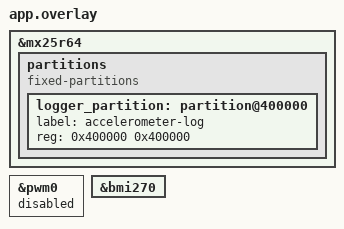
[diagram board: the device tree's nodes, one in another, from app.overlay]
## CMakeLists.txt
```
cmake_minimum_required(VERSION 3.20.0)
find_package(Zephyr REQUIRED HINTS $ENV{ZEPHYR_BASE})
project(thingy53_logger)
target_sources(app PRIVATE src/main.c src/button.c src/storage.c src/usb.c src/writer.c src/imu_temperature.c)
```

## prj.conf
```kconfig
CONFIG_GPIO=y
CONFIG_SENSOR=y
CONFIG_ADXL362=y
CONFIG_ADXL362_ACCEL_RANGE_4G=y
CONFIG_ADXL362_ACCEL_ODR_100=y
CONFIG_ADXL362_TRIGGER_OWN_THREAD=y
CONFIG_ADXL362_THREAD_STACK_SIZE=2048
CONFIG_BMI270=y
CONFIG_FLASH=y
CONFIG_FLASH_MAP=y
CONFIG_NORDIC_QSPI_NOR=y
CONFIG_CRC=y
CONFIG_SERIAL=y
CONFIG_UART_INTERRUPT_DRIVEN=y
CONFIG_UART_LINE_CTRL=y
CONFIG_USB_DEVICE_STACK_NEXT=y
CONFIG_CDC_ACM_SERIAL_INITIALIZE_AT_BOOT=y
CONFIG_CDC_ACM_SERIAL_PRODUCT_STRING="Thingy53 Accelerometer Logger"
CONFIG_CONSOLE=n
CONFIG_UART_CONSOLE=n
CONFIG_LOG=n
CONFIG_BOOT_BANNER=n
CONFIG_BOOTLOADER_MCUBOOT=n
CONFIG_BOARD_ENABLE_CPUNET=n
CONFIG_MAIN_STACK_SIZE=4096
CONFIG_ASSERT=y
```

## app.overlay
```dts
/* Keep the lower half of the 8 MiB external flash outside the logger. */
&mx25r64 {
	partitions {
		compatible = "fixed-partitions";
		#address-cells = <1>;
		#size-cells = <1>;

		logger_partition: partition@400000 {
			label = "accelerometer-log";
			reg = <0x400000 0x400000>;
		};
	};
};

/* The application uses GPIO LEDs, not the board's PWM LED driver. */
&pwm0 {
	status = "disabled";
};

/* The Thingy:53 BMI270 IMU supplies the gyroscope; it shares the SPI bus with the ADXL362. */
&bmi270 {
	status = "okay";
};
```

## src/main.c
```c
#include "button.h"
#include "imu_temperature.h"
#include "sensor_raw.h"
#include "storage.h"
#include "usb.h"
#include "writer.h"

#include <errno.h>
#include <stdio.h>
#include <string.h>
#include <zephyr/drivers/gpio.h>
#include <zephyr/drivers/sensor.h>
#include <zephyr/kernel.h>
#include <zephyr/sys/atomic.h>

static const struct device *const accel = DEVICE_DT_GET(DT_ALIAS(accel0));
static const struct device *const imu = DEVICE_DT_GET(DT_NODELABEL(bmi270));
static const struct gpio_dt_spec button = GPIO_DT_SPEC_GET(DT_ALIAS(sw0), gpios);
static const struct gpio_dt_spec red = GPIO_DT_SPEC_GET(DT_ALIAS(led0), gpios);
static const struct gpio_dt_spec green = GPIO_DT_SPEC_GET(DT_ALIAS(led1), gpios);
static const struct gpio_dt_spec blue = GPIO_DT_SPEC_GET(DT_ALIAS(led2), gpios);
static const struct sensor_trigger trigger = {
	.type = SENSOR_TRIG_DATA_READY,
	.chan = SENSOR_CHAN_ACCEL_XYZ,
};
K_MUTEX_DEFINE(capture_lock);
static bool recording;
static bool downloading;
static bool storage_ready;
static bool fatal;
static int last_error;
static int64_t erase_done_ms;
static atomic_t capture_error;
static uint64_t start_us;
static uint64_t previous_us;
static uint32_t download_page;
static uint32_t download_offset;
static int64_t download_progress;
static uint8_t download_buffer[LOG_PAGE_SIZE] __aligned(4);
static char reply[192];
static size_t reply_size;

static uint64_t now_us(void)
{
	return k_ticks_to_us_floor64(k_uptime_ticks());
}

static void data_ready(const struct device *dev, const struct sensor_trigger *trig)
{
	ARG_UNUSED(trig);
	struct sensor_value xyz[3];
	struct sensor_value gyro[3];
	struct log_sample sample;

	k_mutex_lock(&capture_lock, K_FOREVER);
	uint64_t timestamp = now_us();
	int rc = sensor_sample_fetch(dev);

	if (!rc) {
		rc = sensor_channel_get(dev, SENSOR_CHAN_ACCEL_XYZ, xyz);
	}
	/* The gyroscope runs at 200 Hz, so this read is at most 5 ms old. */
	if (!rc) {
		rc = sensor_sample_fetch(imu);
	}
	if (!rc) {
		rc = sensor_channel_get(imu, SENSOR_CHAN_GYRO_XYZ, gyro);
	}
	if (!rc) {
		rc = imu_temperature_read(&sample.temperature_raw);
	}
	if (recording && !atomic_get(&capture_error)) {
		if (!rc && previous_us && timestamp - previous_us > 15000) {
			rc = -EOVERFLOW;
		}
		previous_us = timestamp;
		if (!rc) {
			sample.time_us = timestamp - start_us;
			for (int i = 0; i < 3; i++) {
				sample.accel[i] = adxl362_raw_from_micro_ms2(sensor_value_to_micro(&xyz[i]));
				sample.gyro[i] = bmi270_raw_from_micro_rad_s(sensor_value_to_micro(&gyro[i]));
			}
			rc = writer_append(&sample);
		}
		if (rc) {
			/* Keep the first cause; later callbacks are ignored until stop. */
			atomic_cas(&capture_error, 0, rc);
		}
	}
	k_mutex_unlock(&capture_lock);
}

static void error(int rc)
{
	if (rc < 0) {
		last_error = rc;
	}
}

static void stop(void)
{
	k_mutex_lock(&capture_lock, K_FOREVER);
	recording = false;
	error(atomic_set(&capture_error, 0));
	k_mutex_unlock(&capture_lock);
	error(writer_flush());
}

static void toggle(void)
{
	if (fatal || downloading) {
		return;
	}
	if (recording) {
		stop();
		return;
	}
	int rc = writer_begin();

	if (rc) {
		error(rc);
		return;
	}
	atomic_clear(&capture_error);
	last_error = 0;
	k_mutex_lock(&capture_lock, K_FOREVER);
	start_us = now_us();
	previous_us = 0;
	recording = true;
	k_mutex_unlock(&capture_lock);
}

static void erase_blink(struct k_timer *timer)
{
	ARG_UNUSED(timer);
	gpio_pin_toggle_dt(&blue);
}

K_TIMER_DEFINE(erase_blink_timer, erase_blink, NULL);

static void erase(void)
{
	if (!storage_ready) {
		return;
	}
	if (recording) {
		stop();
	}
	downloading = false;
	reply_size = 0;
	logger_usb_discard();
	/* The erase blocks for a long time; a timer keeps blue blinking meanwhile. */
	error(gpio_pin_set_dt(&blue, 1));
	k_timer_start(&erase_blink_timer, K_MSEC(250), K_MSEC(250));
	int rc = storage_erase();

	k_timer_stop(&erase_blink_timer);

	if (rc) {
		/* Partial erase requires a reboot/re-scan before appending. */
		fatal = true;
		error(rc);
	} else {
		erase_done_ms = k_uptime_get();
		if (!fatal) {
			last_error = 0;
		}
	}
}

/* After a successful erase, blue flashes three times (150 ms off, 150 ms on). */
static bool erase_flash_active(bool *on)
{
	if (!erase_done_ms) {
		return false;
	}
	int64_t phase = (k_uptime_get() - erase_done_ms) / 150;

	if (phase >= 6) {
		erase_done_ms = 0;
		return false;
	}
	*on = phase & 1;
	return true;
}

static void poll_button(void)
{
	static struct button_state state;
	int value = gpio_pin_get_dt(&button);

	if (value < 0) {
		error(value);
		return;
	}
	switch (button_update(&state, value != 0, k_uptime_get())) {
	case BUTTON_TOGGLE:
		toggle();
		break;
	case BUTTON_ERASE:
		erase();
		break;
	case BUTTON_NONE:
		break;
	}
}

static void poll_usb(void)
{
	char command[32];

	if (!logger_usb_connected()) {
		downloading = false;
		reply_size = 0;
		logger_usb_discard();
		return;
	}
	if (reply_size) {
		if (logger_usb_send(reply, reply_size)) {
			reply_size = 0;
		}
		return;
	}
	if (downloading) {
		if (k_uptime_get() - download_progress > 10000) {
			downloading = false;
			logger_usb_discard();
			error(-ETIMEDOUT);
			return;
		}
		if (download_page == storage.used) {
			memcpy(reply, "END\n", 4);
			reply_size = 4;
			downloading = false;
			return;
		}
		if (!download_offset) {
			int rc = storage_read(download_page, download_buffer);

			if (rc) {
				error(rc);
				downloading = false;
				reply_size = snprintf(reply, sizeof(reply), "ERR read %d\n", rc);
				return;
			}
		}
		if (logger_usb_send(download_buffer + download_offset, 256)) {
			download_progress = k_uptime_get();
			download_offset += 256;
			if (download_offset == LOG_PAGE_SIZE) {
				download_page++;
				download_offset = 0;
			}
		}
		return;
	}
	if (!logger_usb_command(command, sizeof(command))) {
		return;
	}
	if (!strcmp(command, "STATUS")) {
		reply_size = snprintf(reply, sizeof(reply),
			"STATUS %s pages=%u capacity=%u session=%u invalid=%u error=%d\n",
			fatal ? "fault" : recording ? "recording" : "stopped",
			storage.used, storage.capacity, storage.session,
			storage.invalid, last_error);
	} else if (!strcmp(command, "DUMP")) {
		if (recording || fatal) {
			reply_size = snprintf(reply, sizeof(reply), "ERR %s\n",
					      recording ? "recording" : "fault");
		} else {
			downloading = true;
			download_page = 0;
			download_offset = 0;
			download_progress = k_uptime_get();
			reply_size = snprintf(reply, sizeof(reply), "BEGIN %u\n", storage.used);
		}
	} else {
		reply_size = snprintf(reply, sizeof(reply), "ERR unknown-command\n");
	}
}

static int configure_gyro(void)
{
	struct sensor_value odr = {.val1 = 200};
	struct sensor_value range = {.val1 = LOG_GYRO_RANGE_DPS};
	int rc = sensor_attr_set(imu, SENSOR_CHAN_GYRO_XYZ, SENSOR_ATTR_FULL_SCALE, &range);

	if (!rc) {
		rc = sensor_attr_set(imu, SENSOR_CHAN_GYRO_XYZ, SENSOR_ATTR_SAMPLING_FREQUENCY, &odr);
	}
	return rc;
}

int main(void)
{
	const struct gpio_dt_spec *leds[] = {&red, &green, &blue};
	int rc;

	for (size_t i = 0; i < ARRAY_SIZE(leds); i++) {
		if (!gpio_is_ready_dt(leds[i])) {
			return -ENODEV;
		}
		rc = gpio_pin_configure_dt(leds[i], GPIO_OUTPUT_INACTIVE);
		if (rc) {
			return rc;
		}
	}
	rc = logger_usb_init();
	if (rc) {
		error(rc);
		fatal = true;
	}
	rc = storage_init();
	storage_ready = rc == 0;
	if (rc) {
		error(rc);
		fatal = true;
	}
	if (!gpio_is_ready_dt(&button)) {
		rc = -ENODEV;
	} else {
		rc = gpio_pin_configure_dt(&button, GPIO_INPUT);
	}
	if (!rc && (!device_is_ready(accel) || !device_is_ready(imu))) {
		rc = -ENODEV;
	}
	if (!rc) {
		rc = configure_gyro();
	}
	if (!rc) {
		rc = sensor_trigger_set(accel, &trigger, data_ready);
	}
	if (rc) {
		error(rc);
		fatal = true;
	}
	while (true) {
		if (recording) {
			int capture_rc = atomic_set(&capture_error, 0);

			error(writer_take_error());
			if (capture_rc || last_error || writer_full()) {
				error(capture_rc);
				if (!last_error) {
					error(-ENOSPC);
				}
				stop();
			}
		}
		poll_button();
		poll_usb();
		error(gpio_pin_set_dt(&red, last_error != 0 || storage.invalid != 0));
		error(gpio_pin_set_dt(&green, recording));
		bool blue_on = downloading || (!recording && !last_error);
		bool flash_on;

		if (erase_flash_active(&flash_on)) {
			blue_on = flash_on;
		}
		error(gpio_pin_set_dt(&blue, blue_on));
		k_sleep(K_MSEC(1));
	}
	return 0;
}
```

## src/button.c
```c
#include "button.h"

enum button_event button_update(struct button_state *state, bool active, int64_t now_ms)
{
	if (active != state->raw) {
		state->raw = active;
		state->changed = now_ms;
	}
	if (state->raw != state->stable && now_ms - state->changed >= 30) {
		state->stable = state->raw;
		if (state->stable) {
			state->pressed = now_ms;
			state->held = false;
		} else if (!state->held) {
			return BUTTON_TOGGLE;
		}
	}
	if (state->raw && state->stable && !state->held &&
	    now_ms - state->pressed >= 5000) {
		state->held = true;
		return BUTTON_ERASE;
	}
	return BUTTON_NONE;
}
```

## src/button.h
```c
#ifndef LOGGER_BUTTON_H
#define LOGGER_BUTTON_H

#include <stdbool.h>
#include <stdint.h>

enum button_event {
	BUTTON_NONE,
	BUTTON_TOGGLE,
	BUTTON_ERASE,
};

struct button_state {
	bool raw;
	bool stable;
	bool held;
	int64_t changed;
	int64_t pressed;
};

enum button_event button_update(struct button_state *state, bool active, int64_t now_ms);

#endif
```

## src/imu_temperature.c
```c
#include "imu_temperature.h"

#include <errno.h>
#include <zephyr/drivers/spi.h>
#include <zephyr/kernel.h>
#include <zephyr/sys/byteorder.h>

static const struct spi_dt_spec bus = SPI_DT_SPEC_GET(
	DT_NODELABEL(bmi270), SPI_WORD_SET(8) | SPI_TRANSFER_MSB, 0);

int imu_temperature_read(int16_t *raw)
{
	uint8_t address = 0x22 | 0x80;
	uint8_t discarded[2];
	uint8_t bytes[2];
	struct spi_buf tx_buffer = {.buf = &address, .len = 1};
	struct spi_buf rx_buffers[] = {
		/* nrfx needs a real DMA buffer to clock bytes after command TX ends. */
		{.buf = discarded, .len = sizeof(discarded)},
		{.buf = bytes, .len = sizeof(bytes)},
	};
	const struct spi_buf_set tx = {.buffers = &tx_buffer, .count = 1};
	const struct spi_buf_set rx = {.buffers = rx_buffers, .count = 2};
	int rc = spi_transceive_dt(&bus, &tx, &rx);

	if (rc) {
		return rc;
	}
	k_usleep(2);
	int16_t value = (int16_t)sys_get_le16(bytes);

	if (value == INT16_MIN) {
		return -ENODATA;
	}
	*raw = value;
	return 0;
}
```

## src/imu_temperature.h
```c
#ifndef LOGGER_IMU_TEMPERATURE_H
#define LOGGER_IMU_TEMPERATURE_H

#include <stdint.h>

int imu_temperature_read(int16_t *raw);

#endif
```

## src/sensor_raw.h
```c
#ifndef LOGGER_SENSOR_RAW_H
#define LOGGER_SENSOR_RAW_H

#include <stdint.h>

/*
 * Zephyr's sensor API only returns converted values. These helpers undo the
 * drivers' integer conversions so the raw 16-bit counts can be stored. One
 * count is about 19,600 micro-m/s^2 or 1,065 micro-rad/s, far larger than the
 * drivers' rounding error, so rounding to the nearest count is exact.
 */
#define SENSOR_RAW_G_MICRO 9806650LL      /* Zephyr SENSOR_G */
#define SENSOR_RAW_PI_MICRO 3141592LL     /* Zephyr SENSOR_PI */
#define ADXL362_4G_COUNTS_PER_G 500LL     /* ADXL362 driver, +/-4 g range */
#define BMI270_GYRO_FULL_SCALE_COUNTS 32767LL /* BMI270 driver, INT16_MAX */

static inline int16_t sensor_raw_clamp(int64_t counts)
{
	return counts > INT16_MAX ? INT16_MAX : counts < INT16_MIN ? INT16_MIN : (int16_t)counts;
}

static inline int64_t sensor_raw_divide_round(int64_t numerator, int64_t denominator)
{
	return (numerator + (numerator < 0 ? -denominator / 2 : denominator / 2)) / denominator;
}

/* ADXL362 acceleration in micro-m/s^2 to raw counts (driver: counts * G / 500). */
static inline int16_t adxl362_raw_from_micro_ms2(int64_t micro_ms2)
{
	return sensor_raw_clamp(sensor_raw_divide_round(micro_ms2 * ADXL362_4G_COUNTS_PER_G,
							SENSOR_RAW_G_MICRO));
}

/* BMI270 rate in micro-rad/s to raw counts at +/-2000 deg/s. */
static inline int16_t bmi270_raw_from_micro_rad_s(int64_t micro_rad_s)
{
	return sensor_raw_clamp(sensor_raw_divide_round(
		micro_rad_s * 180LL * BMI270_GYRO_FULL_SCALE_COUNTS,
		2000LL * SENSOR_RAW_PI_MICRO));
}

#endif
```

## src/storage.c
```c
#include "storage.h"

#include <errno.h>
#include <string.h>
#include <zephyr/storage/flash_map.h>
#include <zephyr/sys/crc.h>

struct log_storage storage;
static const struct flash_area *area;
static uint8_t page[LOG_PAGE_SIZE] __aligned(4);

static bool erased(const uint8_t *data)
{
	for (size_t i = 0; i < LOG_PAGE_SIZE; i++) {
		if (data[i] != 0xff) {
			return false;
		}
	}
	return true;
}

static bool valid(const uint8_t *data)
{
	const struct log_page_image *image = (const void *)data;
	const struct log_page_header *h = &image->header;
	uint16_t max_count;

	switch (h->version) {
	case LOG_VERSION_1:
		max_count = LOG_V3_SAMPLES_PER_PAGE;
		break;
	case LOG_VERSION_2:
		max_count = LOG_V2_SAMPLES_PER_PAGE;
		if (h->gyro_range_dps != LOG_GYRO_RANGE_DPS) {
			return false;
		}
		break;
	case LOG_VERSION_3:
	case LOG_VERSION:
		max_count = h->version == LOG_VERSION ? LOG_SAMPLES_PER_PAGE : LOG_V3_SAMPLES_PER_PAGE;
		if (h->gyro_range_dps != LOG_GYRO_RANGE_DPS ||
		    h->accel_counts_per_g != LOG_ACCEL_COUNTS_PER_G) {
			return false;
		}
		break;
	default:
		return false;
	}
	return h->magic == LOG_MAGIC && h->count > 0 && h->count <= max_count &&
	       h->session != 0 && h->sample_rate_hz == LOG_SAMPLE_RATE_HZ &&
	       h->range_g == LOG_RANGE_G &&
	       image->crc32 == crc32_ieee(data, LOG_PAGE_SIZE - sizeof(image->crc32));
}

int storage_read(uint32_t index, uint8_t *buffer)
{
	if (index >= storage.capacity) {
		return -EINVAL;
	}
	return flash_area_read(area, index * LOG_PAGE_SIZE, buffer, LOG_PAGE_SIZE);
}

int storage_init(void)
{
	int rc = flash_area_open(PARTITION_ID(logger_partition), &area);

	if (rc) {
		return rc;
	}
	memset(&storage, 0, sizeof(storage));
	if (!flash_area_device_is_ready(area) || area->fa_size % LOG_PAGE_SIZE) {
		return -ENODEV;
	}
	storage.capacity = area->fa_size / LOG_PAGE_SIZE;
	for (uint32_t i = 0; i < storage.capacity; i++) {
		rc = storage_read(i, page);
		if (rc) {
			return rc;
		}
		if (erased(page)) {
			continue;
		}
		/* Never reuse a possibly torn write without an explicit erase. */
		storage.used = i + 1;
		if (!valid(page) || ((const struct log_page_image *)page)->header.page_index != i) {
			storage.invalid++;
			continue;
		}
		uint32_t session = ((const struct log_page_image *)page)->header.session;

		if (session > storage.session) {
			storage.session = session;
		}
	}
	return 0;
}

int storage_begin(void)
{
	if (storage.used == storage.capacity) {
		return -ENOSPC;
	}
	if (storage.session == UINT32_MAX) {
		return -EOVERFLOW;
	}
	storage.session++;
	return 0;
}

void storage_page_reset(struct log_page *p)
{
	memset(p->data, 0xff, sizeof(p->data));
	p->count = 0;
}

int storage_page_add(struct log_page *p, const struct log_sample *sample)
{
	if (p->count == LOG_SAMPLES_PER_PAGE) {
		return -ENOSPC;
	}
	struct log_sample_record *record = &p->image.samples[p->count];

	record->time_us = sample->time_us;
	record->temperature_raw = sample->temperature_raw;
	for (int i = 0; i < 3; i++) {
		record->accel_raw[i] = sample->accel[i];
		record->gyro_raw[i] = sample->gyro[i];
	}
	p->count++;
	return 0;
}

int storage_write_page(struct log_page *p)
{
	struct log_page_header *h = &p->image.header;

	h->magic = LOG_MAGIC;
	h->version = LOG_VERSION;
	h->count = p->count;
	h->session = storage.session;
	h->page_index = p->slot;
	h->sample_rate_hz = LOG_SAMPLE_RATE_HZ;
	h->range_g = LOG_RANGE_G;
	h->gyro_range_dps = LOG_GYRO_RANGE_DPS;
	h->accel_counts_per_g = LOG_ACCEL_COUNTS_PER_G;
	p->image.crc32 = crc32_ieee(p->data, LOG_PAGE_SIZE - sizeof(p->image.crc32));
	int rc = flash_area_write(area, p->slot * LOG_PAGE_SIZE, p->data, LOG_PAGE_SIZE);

	/* A failed write may have programmed some bits. Do not retry that slot. */
	storage.used = p->slot + 1;
	if (rc) {
		storage.invalid++;
	}
	return rc;
}

int storage_erase(void)
{
	int rc = flash_area_erase(area, 0, area->fa_size);

	if (rc) {
		return rc;
	}
	storage.used = 0;
	storage.session = 0;
	storage.invalid = 0;
	return 0;
}
```

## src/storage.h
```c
#ifndef LOGGER_STORAGE_H
#define LOGGER_STORAGE_H

#include <stddef.h>
#include <stdint.h>

#define LOG_PAGE_SIZE 4096U
#define LOG_HEADER_SIZE 32U
#define LOG_SAMPLE_SIZE 22U
#define LOG_SAMPLES_PER_PAGE 184U
#define LOG_MAGIC 0x33474c41U /* "ALG3" when read as little-endian bytes */
#define LOG_VERSION 4U
/*
 * Older pages stay readable: version 1 (accelerometer only, converted values) and
 * version 2 (converted accelerometer + gyroscope, 126 per page), and version 3
 * (raw accelerometer + gyroscope, 203 per page).
 */
#define LOG_VERSION_1 1U
#define LOG_VERSION_2 2U
#define LOG_VERSION_3 3U
#define LOG_V3_SAMPLES_PER_PAGE 203U
#define LOG_V2_SAMPLES_PER_PAGE 126U
#define LOG_SAMPLE_RATE_HZ 100U
#define LOG_RANGE_G 4U
#define LOG_ACCEL_COUNTS_PER_G 500U
#define LOG_GYRO_RANGE_DPS 2000U

/* Sample as captured in RAM; accelerometer and gyroscope are raw 16-bit counts. */
struct log_sample {
	uint64_t time_us;
	int16_t accel[3];
	int16_t gyro[3];
	int16_t temperature_raw; /* BMI270: Celsius = 23 + raw / 512. */
};

/*
 * On-flash layout, little-endian, one page per 4096-byte flash slot. See
 * docs/log-format.md; keep it, docs/thingy53_log.ksy and tools/logger.py in
 * sync with these structures.
 */
struct __attribute__((packed)) log_page_header {
	uint32_t magic;
	uint16_t version;
	uint16_t count;       /* valid samples in this page, 1..184 */
	uint32_t session;     /* recording session, starts at 1 */
	uint32_t page_index;  /* physical slot number of this page */
	uint32_t sample_rate_hz;
	uint32_t range_g;
	uint32_t gyro_range_dps; /* versions 2..4; erased (0xffffffff) in version 1 */
	uint16_t accel_counts_per_g; /* versions 3 and 4 */
	uint16_t reserved;    /* left erased (0xffff) */
};

struct __attribute__((packed)) log_sample_record {
	uint64_t time_us;     /* microseconds since the recording started */
	int16_t accel_raw[3]; /* x, y, z accelerometer counts */
	int16_t gyro_raw[3];  /* x, y, z gyroscope counts */
	int16_t temperature_raw;
};

struct __attribute__((packed)) log_page_image {
	struct log_page_header header;
	struct log_sample_record samples[LOG_SAMPLES_PER_PAGE]; /* unused ones stay 0xff */
	uint8_t padding[12];  /* left erased */
	uint32_t crc32;       /* CRC-32/IEEE of all preceding bytes of the page */
};

_Static_assert(__BYTE_ORDER__ == __ORDER_LITTLE_ENDIAN__, "page format is little-endian");
_Static_assert(sizeof(struct log_page_header) == LOG_HEADER_SIZE, "header size");
_Static_assert(sizeof(struct log_sample_record) == LOG_SAMPLE_SIZE, "sample size");
_Static_assert(sizeof(struct log_page_image) == LOG_PAGE_SIZE, "page size");

struct log_page {
	_Alignas(4) union {
		uint8_t data[LOG_PAGE_SIZE];
		struct log_page_image image;
	};
	uint16_t count;
	uint32_t slot;
};

struct log_storage {
	uint32_t used;
	uint32_t capacity;
	uint32_t session;
	uint32_t invalid;
};

extern struct log_storage storage;

int storage_init(void);
int storage_begin(void);
void storage_page_reset(struct log_page *page);
int storage_page_add(struct log_page *page, const struct log_sample *sample);
int storage_write_page(struct log_page *page);
int storage_erase(void);
int storage_read(uint32_t index, uint8_t *buffer);

#endif
```

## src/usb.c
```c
#include "usb.h"

#include <errno.h>
#include <string.h>
#include <zephyr/device.h>
#include <zephyr/drivers/uart.h>
#include <zephyr/kernel.h>
#include <zephyr/sys/ring_buffer.h>

static const struct device *const uart = DEVICE_DT_GET(DT_NODELABEL(board_cdc_acm_uart));
RING_BUF_DECLARE(tx, 2048);
RING_BUF_DECLARE(rx, 256);
static struct k_spinlock lock;

static void interrupt(const struct device *dev, void *user_data)
{
	ARG_UNUSED(user_data);
	if (!uart_irq_update(dev)) {
		return;
	}
	/* Drain all pending RX bytes, otherwise the driver re-queues this callback. */
	while (uart_irq_rx_ready(dev)) {
		uint8_t buffer[64];
		int n = uart_fifo_read(dev, buffer, sizeof(buffer));

		if (n <= 0) {
			break;
		}
		ring_buf_put(&rx, buffer, n);
	}
	if (uart_irq_tx_ready(dev)) {
		k_spinlock_key_t key = k_spin_lock(&lock);
		uint8_t *data;
		uint32_t size = ring_buf_get_claim(&tx, &data, 256);

		if (size) {
			int n = uart_fifo_fill(dev, data, size);

			ring_buf_get_finish(&tx, n > 0 ? n : 0);
		}
		if (ring_buf_is_empty(&tx)) {
			uart_irq_tx_disable(dev);
		}
		k_spin_unlock(&lock, key);
	}
}

int logger_usb_init(void)
{
	if (!device_is_ready(uart)) {
		return -ENODEV;
	}
	int rc = uart_irq_callback_user_data_set(uart, interrupt, NULL);

	if (rc) {
		return rc;
	}
	/* With a callback set, the CDC ACM driver only starts USB OUT transfers once RX is enabled. */
	uart_irq_rx_enable(uart);
	return 0;
}

bool logger_usb_connected(void)
{
	uint32_t dtr = 0;

	return uart_line_ctrl_get(uart, UART_LINE_CTRL_DTR, &dtr) == 0 && dtr;
}

bool logger_usb_send(const void *data, size_t size)
{
	if (!logger_usb_connected()) {
		return false;
	}
	k_spinlock_key_t key = k_spin_lock(&lock);
	bool fits = ring_buf_space_get(&tx) >= size;

	if (fits) {
		ring_buf_put(&tx, data, size);
		uart_irq_tx_enable(uart);
	}
	k_spin_unlock(&lock, key);
	return fits;
}

void logger_usb_discard(void)
{
	k_spinlock_key_t key = k_spin_lock(&lock);

	uart_irq_tx_disable(uart);
	ring_buf_reset(&tx);
	k_spin_unlock(&lock, key);
}

bool logger_usb_command(char *command, size_t capacity)
{
	static char input[32];
	static size_t length;
	static bool overflow;
	uint8_t c;

	while (ring_buf_get(&rx, &c, 1) == 1) {
		if (c == '\r') {
			continue;
		}
		if (c == '\n') {
			if (overflow || length >= capacity) {
				strncpy(command, "INVALID", capacity);
				command[capacity - 1] = '\0';
			} else {
				memcpy(command, input, length);
				command[length] = '\0';
			}
			length = 0;
			overflow = false;
			return true;
		}
		if (length < sizeof(input) - 1) {
			input[length++] = c;
		} else {
			overflow = true;
		}
	}
	return false;
}
```

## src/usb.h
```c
#ifndef LOGGER_USB_H
#define LOGGER_USB_H

#include <stdbool.h>
#include <stddef.h>

int logger_usb_init(void);
bool logger_usb_connected(void);
bool logger_usb_send(const void *data, size_t size);
bool logger_usb_command(char *command, size_t capacity);
void logger_usb_discard(void);

#endif
```

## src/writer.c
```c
#include "writer.h"

#include <errno.h>
#include <zephyr/kernel.h>

/*
 * Two RAM pages ping-pong: the producer fills pages[fill] while the writer
 * thread programs the other one into flash. A single token (spare) represents
 * the page that is free to switch to, so ownership never overlaps and no lock
 * is held while flash is busy.
 */
static struct log_page pages[2];
static struct log_page *fill = &pages[0];
static uint32_t reserved;
static atomic_t write_error;

K_SEM_DEFINE(spare, 1, 1);
K_MSGQ_DEFINE(ready, sizeof(struct log_page *), 1, sizeof(struct log_page *));

static int submit(k_timeout_t wait)
{
	if (reserved == storage.capacity) {
		return -ENOSPC;
	}
	if (k_sem_take(&spare, wait)) {
		return -EBUSY;
	}
	fill->slot = reserved++;
	k_msgq_put(&ready, &fill, K_NO_WAIT);
	fill = fill == &pages[0] ? &pages[1] : &pages[0];
	return 0;
}

int writer_begin(void)
{
	int rc = storage_begin();

	if (rc) {
		return rc;
	}
	reserved = storage.used;
	atomic_clear(&write_error);
	storage_page_reset(&pages[0]);
	storage_page_reset(&pages[1]);
	fill = &pages[0];
	return 0;
}

int writer_append(const struct log_sample *sample)
{
	if (reserved == storage.capacity) {
		return -ENOSPC;
	}
	int rc = storage_page_add(fill, sample);

	if (rc == 0 && fill->count == LOG_SAMPLES_PER_PAGE) {
		return submit(K_NO_WAIT);
	}
	return rc;
}

int writer_flush(void)
{
	int rc = 0;

	if (fill->count) {
		rc = submit(K_FOREVER);
	}
	/* The spare token comes back only after the last queued page is written. */
	k_sem_take(&spare, K_FOREVER);
	k_sem_give(&spare);
	int write_rc = writer_take_error();

	return rc ? rc : write_rc;
}

int writer_take_error(void)
{
	return atomic_set(&write_error, 0);
}

bool writer_full(void)
{
	return reserved == storage.capacity;
}

void writer_process_one(void)
{
	struct log_page *page;

	k_msgq_get(&ready, &page, K_FOREVER);
	int rc = storage_write_page(page);

	if (rc) {
		atomic_cas(&write_error, 0, rc);
	}
	storage_page_reset(page);
	k_sem_give(&spare);
}

static void writer_thread(void *a, void *b, void *c)
{
	ARG_UNUSED(a);
	ARG_UNUSED(b);
	ARG_UNUSED(c);
	while (true) {
		writer_process_one();
	}
}

/* Lower priority than the accelerometer thread (10) so sampling always preempts it. */
K_THREAD_DEFINE(writer_tid, 2048, writer_thread, NULL, NULL, NULL, 11, 0, 0);
```

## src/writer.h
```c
#ifndef LOGGER_WRITER_H
#define LOGGER_WRITER_H

#include "storage.h"

#include <stdbool.h>

/* Start a session: reserves a session id and resets both RAM pages. */
int writer_begin(void);

/*
 * Producer side, called by one thread at a time while recording. Never blocks
 * on flash. Returns -EBUSY if a full page could not be handed over because the
 * writer thread is still busy with the previous page, and -ENOSPC when full.
 */
int writer_append(const struct log_sample *sample);

/* Hand over the partial page and wait until all pages are in flash. */
int writer_flush(void);

/* Returns and clears the first flash write error reported by the writer thread. */
int writer_take_error(void);

/* True once every page slot is written or queued for writing. */
bool writer_full(void);

/* Consumer side; runs forever in the writer thread. Exposed for host tests. */
void writer_process_one(void);

#endif
```
